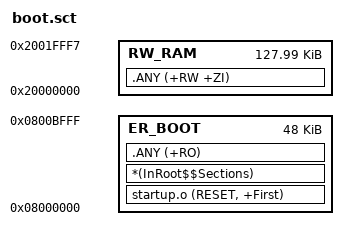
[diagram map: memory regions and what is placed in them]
LR_BOOT 0x08000000 0x0000C000
{
    ER_BOOT 0x08000000 0x0000C000
    {
        startup.o (RESET, +First)
        *(InRoot$$Sections)
        .ANY (+RO)
    }
    RW_RAM 0x20000000 0x0001FFF8
    {
        .ANY (+RW +ZI)
    }
}
